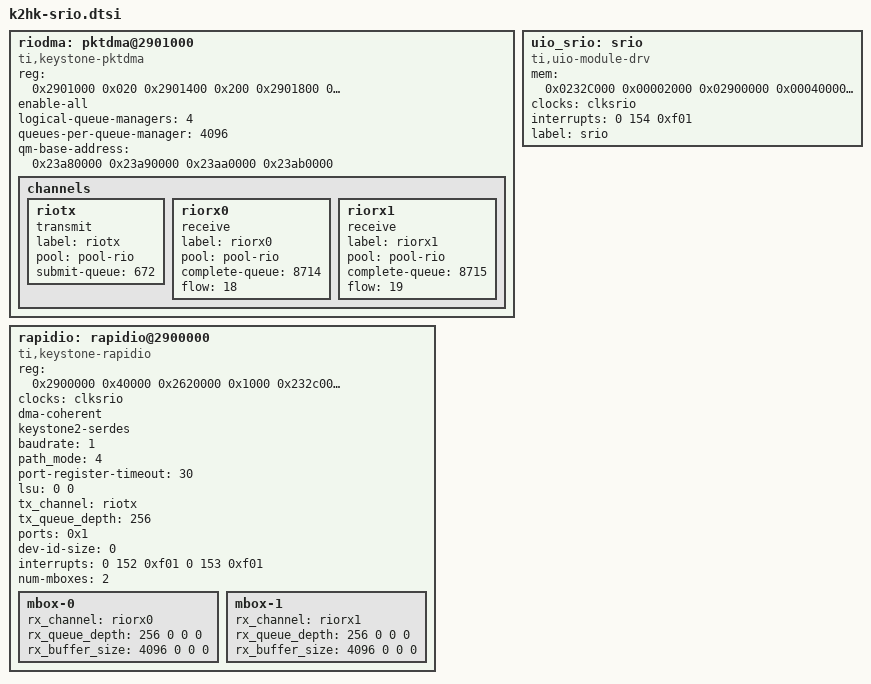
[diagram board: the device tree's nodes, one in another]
riodma: pktdma@2901000 {
        compatible = "ti,keystone-pktdma";
        reg = <0x2901000 0x020          /* 0 - global  */
               0x2901400 0x200          /* 1 - txchan  */
               0x2901800 0x200          /* 2 - rxchan  */
               0x2901c00 0x200          /* 3 - txsched */
               0x2902000 0x280>;        /* 4 - rxflow  */
        /* clocks = <&clkpktproc>; */
        enable-all;
        /* debug; */
        /* dma-coherent; */

        logical-queue-managers  = <4>;
        queues-per-queue-manager = <4096>;
        qm-base-address = <0x23a80000 0x23a90000
                           0x23aa0000 0x23ab0000>;

        channels {
		riotx {
			transmit;
                        label           = "riotx";
                        pool            = "pool-rio";
                        submit-queue    = <672>;
                        /*complete-queue        = <657>;*/
                        /*debug;*/
                };
		riorx0 {
                        receive;
                        label           = "riorx0";
                        pool            = "pool-rio";
                        /*debug;*/
                        complete-queue  = <8714>;
                        flow            = <18>;
                };
		riorx1 {
                        receive;
                        label           = "riorx1";
                        pool            = "pool-rio";
                        /*debug;*/
                        complete-queue  = <8715>;
                        flow            = <19>;
                };
	};
};

rapidio: rapidio@2900000 {
	#address-cells = <1>;
        #size-cells = <1>;
        reg = <0x2900000 0x40000        /* rio regs */
               0x2620000 0x1000         /* boot config regs */
	       0x232c000 0x2000>;       /* serdes config regs */
        clocks = <&clksrio>;
        clock-names = "clk_srio";
        compatible = "ti,keystone-rapidio";
	dma-coherent;

        keystone2-serdes;
        baudrate  = <1>; /* 2.5Gbps */
        path_mode = <4>; /* 1 port in 4x */
	port-register-timeout = <30>; /* 30 seconds */
	lsu       = <0 0>; /* DIO and maintenance LSUs */

        tx_channel = "riotx";
        tx_queue_depth = <256>;

        ports = <0x1>;      /* bitfield of port(s) to probe */
        dev-id-size = <0>;  /* RapidIO common transport system
                             * size.
                             * 0 - Small size. 8-bit deviceID
                             *     fields. 256 devices.
                             * 1 - Large size, 16-bit deviceID
                             *     fields. 65536 devices.
                             */
	interrupts = <0 152 0xf01 0 153 0xf01>; /* RIO and LSU IRQs */

        num-mboxes = <2>;

        mbox-0 {
	        rx_channel = "riorx0";
                rx_queue_depth  = <256 0 0 0>;
                rx_buffer_size  = <4096 0 0 0>;
                /*stream_id = <0>;*/
        };

        mbox-1 {
	        rx_channel = "riorx1";
                rx_queue_depth  = <256 0 0 0>;
                rx_buffer_size  = <4096 0 0 0>;
                /*stream_id = <1>;*/
        };
};

uio_srio: srio {
	compatible = "ti,uio-module-drv";
	mem  = <0x0232C000 0x00002000
		0x02900000 0x00040000
		0x0232C000 0x00002000>;
	clocks=<&clksrio>;
	interrupts = <0 154 0xf01>;
	label = "srio";
};
